# HM1030 register map
File version: 0.1
Registers are 32-bit, read-write, reset 0x0 unless marked. A register's access mark holds for its fields unless they carry their own. Offsets are from the block's base; [hi:lo] are bit positions; lines under a group give offsets from that group; {n}, {i} and the like mark numbered series.

## FLASH — Registers group
Base 0x4006F000
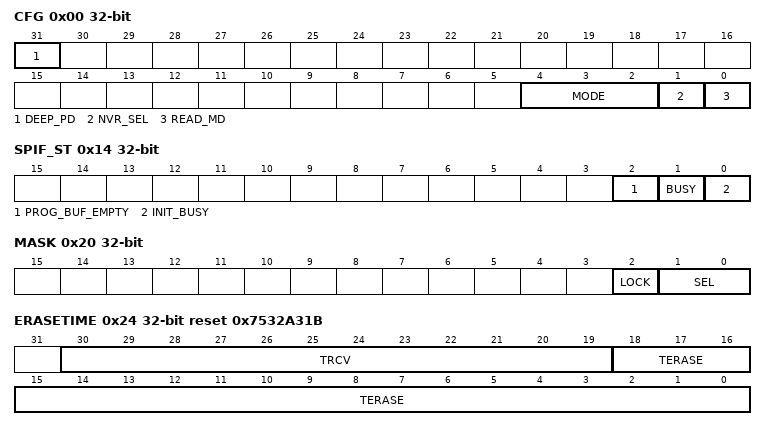
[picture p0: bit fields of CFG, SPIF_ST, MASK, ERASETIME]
0x00 CFG
  [31] DEEP_PD — 配置FLASH进入deep_power_down模式
  [4:2] MODE — 操作模式配置寄存器
  [1] NVR_SEL — NVR区选择
  [0] READ_MD — 读速率模式选择
0x04 ADDR — 地址寄存器
  [13:0] ADDR — 18位地址
0x08 WDATA — 写数据寄存器
0x10 START — 操作启动控制位
  [0] START
0x14 SPIF_ST — 状态寄存器
  [2] PROG_BUF_EMPTY ro — 编程数据缓存寄存器空状态标志
  [1] BUSY — 控制器忙标志
  [0] INIT_BUSY — FLASH初始化忙标志
0x18 LOCK — 操作锁控制
  [7:0] LOCK
0x1C UNLOCK — 操作解锁控制
  [7:0] UNLOCK
0x20 MASK — MASK选择
  [2] LOCK — 选择锁定控制
  [1:0] SEL — 选择
0x24 ERASETIME reset 0x7532A31B — 时间寄存器
  [30:19] TRCV — FLASH扇区擦（全片擦）时，TRCV时间寄存器
  [18:0] TERASE — FLASH扇区擦（全片擦）时，TERASE（TSCE）时间寄存器
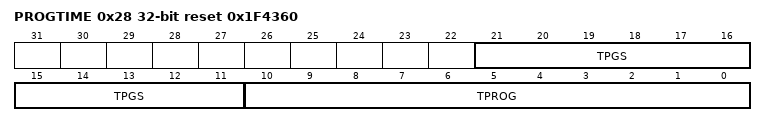
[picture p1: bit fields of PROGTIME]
0x28 PROGTIME reset 0x1F4360 — 时间寄存器
  [21:11] TPGS — FLASH编程操作时的TPGS时间控制寄存器
  [10:0] TPROG — FLASH编程操作时的TPROG时间控制寄存器

## PORT — Registers group
Base 0x400B0000
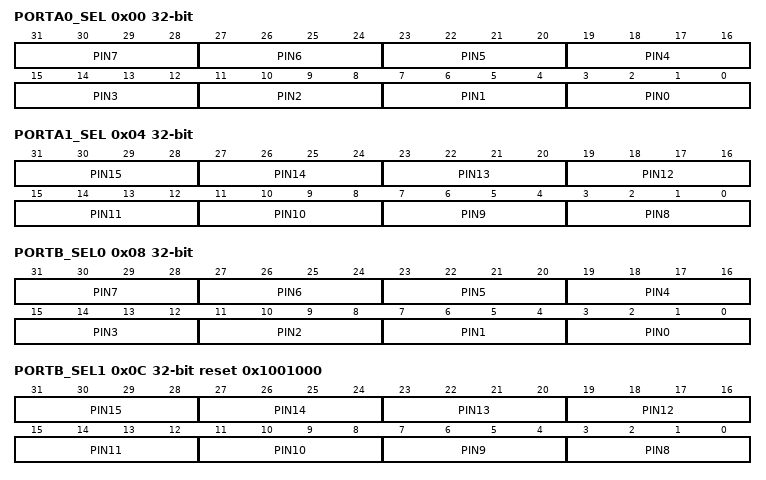
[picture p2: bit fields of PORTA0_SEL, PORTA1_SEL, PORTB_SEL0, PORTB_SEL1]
0x00 PORTA0_SEL — PORTA 功能选择寄存器 0
  [4n+3:4n] PIN{n} (n=0..7)
0x04 PORTA1_SEL — PORTA 功能选择寄存器 1
  [4n-29:4n-32] PIN{n} (n=8..15)
0x08 PORTB_SEL0 — PORTB 功能选择寄存器 0
  [4n+3:4n] PIN{n} (n=0..7)
0x0C PORTB_SEL1 reset 0x1001000 — PORTB 功能选择寄存器 1
  [4n-29:4n-32] PIN{n} (n=8..15)
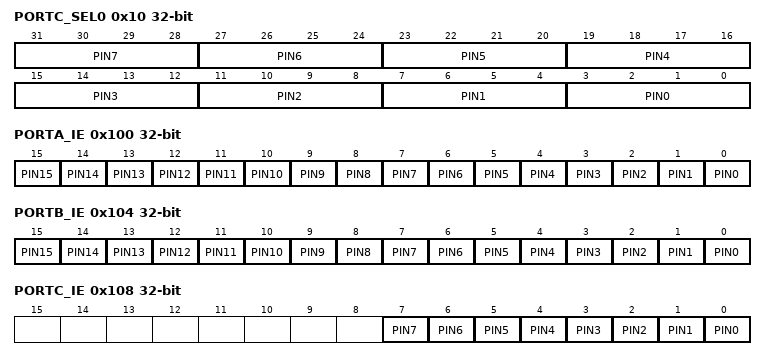
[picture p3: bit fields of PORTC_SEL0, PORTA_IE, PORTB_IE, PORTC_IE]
0x10 PORTC_SEL0 — PORTC 功能选择寄存器 0
  [4n+3:4n] PIN{n} (n=0..7)
0x100 PORTA_IE — PORTA Input Enable register 0 Input Disable 1 Input Enable
  [n] PIN{n} (n=0..15)
0x104 PORTB_IE — PORTB Input Enable register 0 Input Disable 1 Input Enable
  [n] PIN{n} (n=0..15)
0x108 PORTC_IE — PORTC Input Enable register 0 Input Disable 1 Input Enable
  [n] PIN{n} (n=0..7)
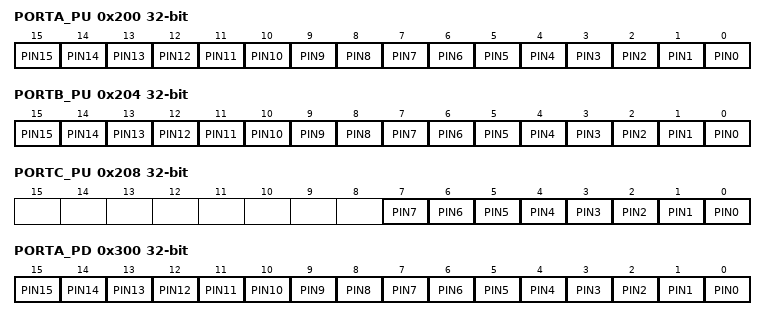
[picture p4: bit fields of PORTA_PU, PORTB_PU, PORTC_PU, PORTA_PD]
0x200 PORTA_PU — Pull_Up Enable register 0 Pull_Up Disable 1 Pull_Up Enable
  [n] PIN{n} (n=0..15)
0x204 PORTB_PU — Pull_Up Enable register 0 Pull_Up Disable 1 Pull_Up Enable
  [n] PIN{n} (n=0..15)
0x208 PORTC_PU — Pull_Up Enable register 0 Pull_Up Disable 1 Pull_Up Enable
  [n] PIN{n} (n=0..7)
0x300 PORTA_PD — Pull_Down Enable register 0 Pull_Down Disable 1 Pull_Down Enable
  [n] PIN{n} (n=0..15)
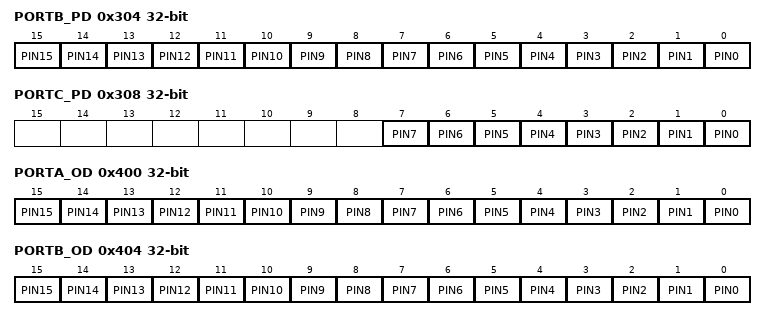
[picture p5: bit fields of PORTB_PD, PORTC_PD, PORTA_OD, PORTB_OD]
0x304 PORTB_PD — Pull_Down Enable register 0 Pull_Down Disable 1 Pull_Down Enable
  [n] PIN{n} (n=0..15)
0x308 PORTC_PD — Pull_Down Enable register 0 Pull_Down Disable 1 Pull_Down Enable
  [n] PIN{n} (n=0..7)
0x400 PORTA_OD — Open_Drain Enable register 0 Open_Drain Disable 1 Open_Drain Enable
  [n] PIN{n} (n=0..15)
0x404 PORTB_OD — Open_Drain Enable register 0 Open_Drain Disable 1 Open_Drain Enable
  [n] PIN{n} (n=0..15)
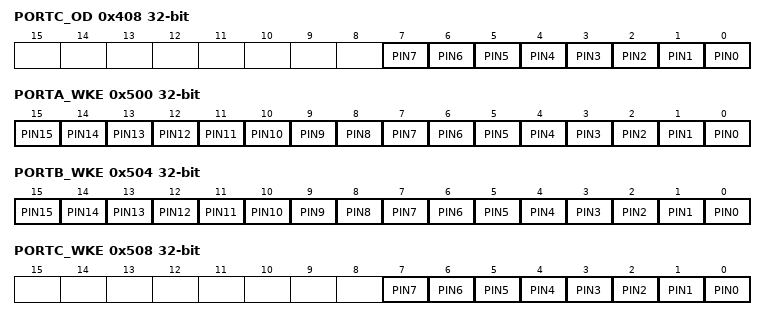
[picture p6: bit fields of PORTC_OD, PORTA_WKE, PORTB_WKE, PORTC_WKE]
0x408 PORTC_OD — Open_Drain Enable register 0 Open_Drain Disable 1 Open_Drain Enable
  [n] PIN{n} (n=0..7)
0x500 PORTA_WKE — WakeUp Enable register 0 WakeUp Disable 1 WakeUp Enable
  [n] PIN{n} (n=0..15)
0x504 PORTB_WKE — WakeUp Enable register 0 WakeUp Disable 1 WakeUp Enable
  [n] PIN{n} (n=0..15)
0x508 PORTC_WKE — WakeUp Enable register 0 WakeUp Disable 1 WakeUp Enable
  [n] PIN{n} (n=0..7)
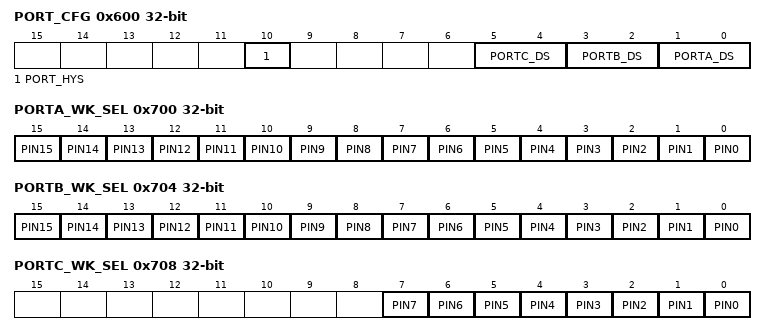
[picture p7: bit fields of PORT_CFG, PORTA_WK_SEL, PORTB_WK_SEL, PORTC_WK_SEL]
0x600 PORT_CFG — Configure register
  [10] PORT_HYS — PORT 输入迟滞等级选择
  [5:4] PORTC_DS — PORTC 驱动能力选择寄存器
  [3:2] PORTB_DS — PORTB 驱动能力选择寄存器
  [1:0] PORTA_DS — PORTA 驱动能力选择寄存器
0x700 PORTA_WK_SEL — PORTA唤醒功能沿配置
  [n] PIN{n} (n=0..15)
0x704 PORTB_WK_SEL — PORTB唤醒功能沿配置
  [n] PIN{n} (n=0..15)
0x708 PORTC_WK_SEL — PORTC唤醒功能沿配置
  [n] PIN{n} (n=0..7)

## PWMBASE0 — Registers group
Base 0x400B1000
Same registers: PWMBASE1 0x400B1800
0x00 EN — PWMBASE使能寄存器
  [0] COUNTER_EN — PWMBASE计数器使能寄存器
0x04 PWMBASE_DIV — PWMBASE时钟预分频寄存器
  [15:0] PWMBASE_DIV — PWMBASE计数时钟预分频寄存器
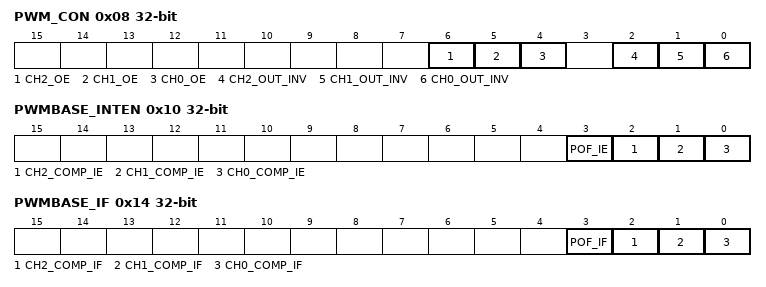
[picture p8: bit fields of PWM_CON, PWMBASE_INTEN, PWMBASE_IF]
0x08 PWM_CON — PWMBASE输出配置寄存器
  [6] CH2_OE — CH2通道波形输出使能
  [5] CH1_OE — CH1通道波形输出使能
  [4] CH0_OE — CH0通道波形输出使能
  [2] CH2_OUT_INV — CH2输出极性是否翻转寄存器
  [1] CH1_OUT_INV — CH1输出极性是否翻转寄存器
  [0] CH0_OUT_INV — PWM0CH0输出极性是否翻转寄存器
0x0C PWMBASE_PERIOD — PWMBASE周期配置寄存器
  [15:0] PWM_PERIOD — PWM输出周期配置寄存器
0x10 PWMBASE_INTEN
  [3] POF_IE — 周期溢出中断使能
  [2] CH2_COMP_IE — CH2到达翻转点中断使能
  [1] CH1_COMP_IE — CH1到达翻转点中断使能
  [0] CH0_COMP_IE — CH0到达翻转点中断使能
0x14 PWMBASE_IF
  [3] POF_IF — 周期溢出中断状态
  [2] CH2_COMP_IF — CH2到达翻转点状态
  [1] CH1_COMP_IF — CH1到达翻转点状态
  [0] CH0_COMP_IF — CH0到达翻转点状态
0x18 PWMBASE_CNT ro — PWMBASE当前计数值寄存器
  [15:0] PWMBASE_CNT — PWMBASE计数器当前计数值寄存器
{0x20+0x10*i} PWMBASE_CH{i}_COMP (i=0..2) — PWMBASE通道{i}翻转点配置寄存器
  [15:0] CH{i}_COMP — CH{i}翻转点配置寄存器
